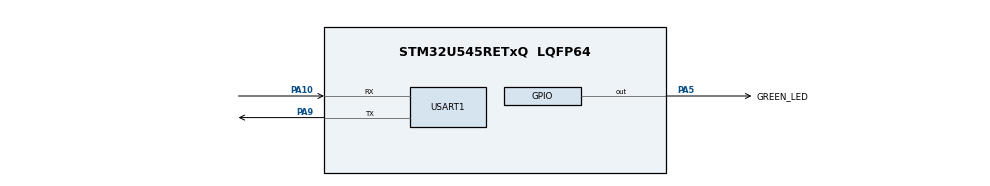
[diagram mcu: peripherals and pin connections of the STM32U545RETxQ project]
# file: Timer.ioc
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CORTEX_M33_NS.userName=CORTEX_M33
Mcu.Family=STM32U5
Mcu.Name=STM32U545RETxQ
Mcu.Package=LQFP64
NVIC.PriorityGroup=NVIC_PRIORITYGROUP_4
PA10.Mode=Asynchronous
PA10.Signal=USART1_RX
PA5.GPIO_Label=GREEN_LED
PA5.Signal=GPIO_Output
PA9.Mode=Asynchronous
PA9.Signal=USART1_TX
PWR.PowerMode=PWR_SMPS_SUPPLY
ProjectManager.HeapSize=0x200
ProjectManager.StackSize=0x400
ProjectManager.TargetToolchain=STM32CubeIDE
RCC.ADCFreq_Value=16000000
RCC.DACCLockSelectionVirtual=RCC_DAC1CLKSOURCE_LSI
RCC.DACCLockSelectionVirtualString=RCC_DAC1CLKSOURCE_LSI
RCC.EPOD_VALUE=4000000
RCC.HSE_VALUE=16000000
RCC.HSI48_VALUE=48000000
RCC.HSI_VALUE=16000000
RCC.LSE_VALUE=32768
RCC.LSIDIV_VALUE=32000
RCC.MSI_VALUE=4000000
RCC.USBFreq_Value=48000000
RCC.VCOOutputFreq_Value=516000000
TIM15.PeriodNoDither=65536-1
TIM15.Prescaler=4-1
USART1.VirtualMode-Asynchronous=VM_ASYNC
VP_ICACHE_VS_ICACHE.Mode=DirectMappedCache
VP_LPBAMQUEUE_VS_QUEUE.Mode=QUEUEMODE
VP_MEMORYMAP_VS_MEMORYMAP.Mode=CurAppReg
VP_NUCLEO-U545RE-Q_VS_BSP_COMMON.Mode=COMMON
VP_PWR_VS_LPOM.Mode=PowerOptimisation
VP_PWR_VS_SECSignals.Mode=Security/Privilege
VP_TIM15_VS_ClockSourceINT.Mode=Internal
board=NUCLEO-U545RE-Q

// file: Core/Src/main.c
/* USER CODE BEGIN Header */
/**
  ******************************************************************************
  * @file           : main.c
  * @brief          : Main program body
  ******************************************************************************
  * @attention
  *
  * Copyright (c) 2026 STMicroelectronics.
  * All rights reserved.
  *
  * This software is licensed under terms that can be found in the LICENSE file
  * in the root directory of this software component.
  * If no LICENSE file comes with this software, it is provided AS-IS.
  *
  ******************************************************************************
  */
/* USER CODE END Header */
#include "main.h"

/* USER CODE BEGIN Includes */
#include <stdio.h>

/* USER CODE END Includes */

TIM_HandleTypeDef htim15;

UART_HandleTypeDef huart1;

void SystemClock_Config(void);
static void SystemPower_Config(void);
static void MX_GPIO_Init(void);
static void MX_ICACHE_Init(void);
static void MX_USART1_UART_Init(void);
static void MX_TIM15_Init(void);

int main(void)
{

  /* USER CODE BEGIN 1 */
	char uart_buf[50];
	int uart_buff_len;
	uint16_t timer_val;
  /* USER CODE END 1 */

  /* MCU Configuration--------------------------------------------------------*/

  /* Reset of all peripherals, Initializes the Flash interface and the Systick. */
  HAL_Init();

  /* Configure the System Power */
  SystemPower_Config();

  /* Configure the system clock */
  SystemClock_Config();

  /* Initialize all configured peripherals */
  MX_GPIO_Init();
  MX_ICACHE_Init();
  MX_USART1_UART_Init();
  MX_TIM15_Init();
  /* USER CODE BEGIN 2 */
  // SPLASH MESSAGE
  uart_buff_len = sprintf(uart_buf, "Timer\r\n");
  HAL_UART_Transmit(&huart1, (uint8_t *)uart_buf, uart_buff_len, HAL_MAX_DELAY);
   // Starting the timer
  HAL_TIM_Base_Start(&htim15);

  /* USER CODE END 2 */

  /* Infinite loop */
  /* USER CODE BEGIN WHILE */
  while (1)
  {
	  timer_val = __HAL_TIM_GET_COUNTER(&htim15);
	  HAL_Delay(50); //ms
	  timer_val = __HAL_TIM_GET_COUNTER(&htim15) - timer_val;

	  uart_buff_len = sprintf(uart_buf, "%u us\r\n", timer_val);
	  HAL_UART_Transmit(&huart1, (uint8_t *)uart_buf, uart_buff_len, HAL_MAX_DELAY);

	  HAL_Delay(1000); //ms

    /* USER CODE END WHILE */

  }
}

void SystemClock_Config(void)
{
  RCC_OscInitTypeDef RCC_OscInitStruct = {0};
  RCC_ClkInitTypeDef RCC_ClkInitStruct = {0};

  /** Configure the main internal regulator output voltage
  */
  if (HAL_PWREx_ControlVoltageScaling(PWR_REGULATOR_VOLTAGE_SCALE4) != HAL_OK)
  {
    Error_Handler();
  }

  /** Initializes the CPU, AHB and APB buses clocks
  */
  RCC_OscInitStruct.OscillatorType = RCC_OSCILLATORTYPE_MSI;
  RCC_OscInitStruct.MSIState = RCC_MSI_ON;
  RCC_OscInitStruct.MSICalibrationValue = RCC_MSICALIBRATION_DEFAULT;
  RCC_OscInitStruct.MSIClockRange = RCC_MSIRANGE_4;
  RCC_OscInitStruct.PLL.PLLState = RCC_PLL_NONE;
  if (HAL_RCC_OscConfig(&RCC_OscInitStruct) != HAL_OK)
  {
    Error_Handler();
  }

  /** Initializes the CPU, AHB and APB buses clocks
  */
  RCC_ClkInitStruct.ClockType = RCC_CLOCKTYPE_HCLK|RCC_CLOCKTYPE_SYSCLK
                              |RCC_CLOCKTYPE_PCLK1|RCC_CLOCKTYPE_PCLK2
                              |RCC_CLOCKTYPE_PCLK3;
  RCC_ClkInitStruct.SYSCLKSource = RCC_SYSCLKSOURCE_MSI;
  RCC_ClkInitStruct.AHBCLKDivider = RCC_SYSCLK_DIV1;
  RCC_ClkInitStruct.APB1CLKDivider = RCC_HCLK_DIV1;
  RCC_ClkInitStruct.APB2CLKDivider = RCC_HCLK_DIV1;
  RCC_ClkInitStruct.APB3CLKDivider = RCC_HCLK_DIV1;

  if (HAL_RCC_ClockConfig(&RCC_ClkInitStruct, FLASH_LATENCY_0) != HAL_OK)
  {
    Error_Handler();
  }
}

/**
  * @brief Power Configuration
  * @retval None
  */
static void SystemPower_Config(void)
{

  /*
   * Switch to SMPS regulator instead of LDO
   */
  if (HAL_PWREx_ConfigSupply(PWR_SMPS_SUPPLY) != HAL_OK)
  {
    Error_Handler();
  }
}

static void MX_ICACHE_Init(void)
{

  /** Enable instruction cache in 1-way (direct mapped cache)
  */
  if (HAL_ICACHE_ConfigAssociativityMode(ICACHE_1WAY) != HAL_OK)
  {
    Error_Handler();
  }
  if (HAL_ICACHE_Enable() != HAL_OK)
  {
    Error_Handler();
  }

}

static void MX_TIM15_Init(void)
{

  TIM_ClockConfigTypeDef sClockSourceConfig = {0};
  TIM_MasterConfigTypeDef sMasterConfig = {0};

  htim15.Instance = TIM15;
  htim15.Init.Prescaler = 4-1;
  htim15.Init.CounterMode = TIM_COUNTERMODE_UP;
  htim15.Init.Period = 65535;
  htim15.Init.ClockDivision = TIM_CLOCKDIVISION_DIV1;
  htim15.Init.RepetitionCounter = 0;
  htim15.Init.AutoReloadPreload = TIM_AUTORELOAD_PRELOAD_DISABLE;
  if (HAL_TIM_Base_Init(&htim15) != HAL_OK)
  {
    Error_Handler();
  }
  sClockSourceConfig.ClockSource = TIM_CLOCKSOURCE_INTERNAL;
  if (HAL_TIM_ConfigClockSource(&htim15, &sClockSourceConfig) != HAL_OK)
  {
    Error_Handler();
  }
  sMasterConfig.MasterOutputTrigger = TIM_TRGO_RESET;
  sMasterConfig.MasterSlaveMode = TIM_MASTERSLAVEMODE_DISABLE;
  if (HAL_TIMEx_MasterConfigSynchronization(&htim15, &sMasterConfig) != HAL_OK)
  {
    Error_Handler();
  }

}

static void MX_USART1_UART_Init(void)
{

  huart1.Instance = USART1;
  huart1.Init.BaudRate = 115200;
  huart1.Init.WordLength = UART_WORDLENGTH_8B;
  huart1.Init.StopBits = UART_STOPBITS_1;
  huart1.Init.Parity = UART_PARITY_NONE;
  huart1.Init.Mode = UART_MODE_TX_RX;
  huart1.Init.HwFlowCtl = UART_HWCONTROL_NONE;
  huart1.Init.OverSampling = UART_OVERSAMPLING_16;
  huart1.Init.OneBitSampling = UART_ONE_BIT_SAMPLE_DISABLE;
  huart1.Init.ClockPrescaler = UART_PRESCALER_DIV1;
  huart1.AdvancedInit.AdvFeatureInit = UART_ADVFEATURE_NO_INIT;
  if (HAL_UART_Init(&huart1) != HAL_OK)
  {
    Error_Handler();
  }
  if (HAL_UARTEx_SetTxFifoThreshold(&huart1, UART_TXFIFO_THRESHOLD_1_8) != HAL_OK)
  {
    Error_Handler();
  }
  if (HAL_UARTEx_SetRxFifoThreshold(&huart1, UART_RXFIFO_THRESHOLD_1_8) != HAL_OK)
  {
    Error_Handler();
  }
  if (HAL_UARTEx_DisableFifoMode(&huart1) != HAL_OK)
  {
    Error_Handler();
  }

}

static void MX_GPIO_Init(void)
{
  GPIO_InitTypeDef GPIO_InitStruct = {0};

  /* GPIO Ports Clock Enable */
  __HAL_RCC_GPIOA_CLK_ENABLE();

  /*Configure GPIO pin Output Level */
  HAL_GPIO_WritePin(GREEN_LED_GPIO_Port, GREEN_LED_Pin, GPIO_PIN_RESET);

  /*Configure GPIO pin : GREEN_LED_Pin */
  GPIO_InitStruct.Pin = GREEN_LED_Pin;
  GPIO_InitStruct.Mode = GPIO_MODE_OUTPUT_PP;
  GPIO_InitStruct.Pull = GPIO_NOPULL;
  GPIO_InitStruct.Speed = GPIO_SPEED_FREQ_LOW;
  HAL_GPIO_Init(GREEN_LED_GPIO_Port, &GPIO_InitStruct);

}

void Error_Handler(void)
{
  __disable_irq();
  while (1)
  {
  }
}
